# MEC1322 register map
Vendor: Microchip Technology Inc.; Series: ARMCM4F; File version: 1.0
CPU: CM4 r1p0, little endian, MPU, FPU, 3 interrupt priority bits
Registers are 32-bit, read-write, reset 0x0 unless marked. A register's access mark holds for its fields unless they carry their own. Offsets are from the block's base; [hi:lo] are bit positions; {n}, {i} and the like mark numbered series.

## BC_LINK — This block provides BC-Link? connectivity to a slave device. The BC-Link protocol includes a start bit to signal the beginning of a message and a turnaround (TAR) period for bus transfer between the Master and Companion devices.
Base 0x4000BC00
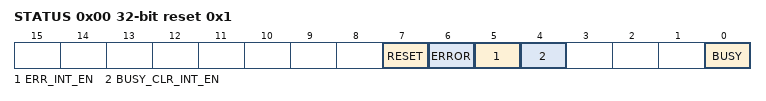
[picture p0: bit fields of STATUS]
0x00 STATUS reset 0x1 — BC-Link Status
  [7] RESET — When this bit is '1'the BC_Link Master Interface will be placed in reset and be held in reset until this bit is cleared to '0'. Setting RESET to '1' causes the BUSY bit to be set to '1'. The BUSY remains set to '1' until the reset operation of the BC Interface is completed, which takes approximately 48 BC clocks.
  [6] ERROR — This bit indicates that a BC Bus Error has occurred. (R/WC)
  [5] ERR_INT_EN — This bit is an enable for generating an interrupt when the BC_ERR bit is set by hardware. When this bit is '1', the interrupt signal is enabled. When this bit is '0', the interrupt is disabled.
  [4] BUSY_CLR_INT_EN — This bit is an enable for generating an interrupt when the BUSY bit in this register is cleared by hardware. When this bit is set to '1', the interrupt signal is enabled. When the this bit is cleared to '0', the interrupt is disabled. When enabled, the interrupt occurs after a BC Bus read or write.
  [0] BUSY read — This bit is asserted to '1' when the BC interface is transferring data and on reset.
0x04 ADDRESS — BC-Link Address Register [7:0] Address in the Companion for the BC-Link transaction.
0x08 DATA — BC-Link Data Register [7:0] this register hold data used in a BC-Link transaction.
0x0C CLOCK_SELECT — BC-Link Clock Select Register [7:0] DIVIDER The BC Clock is set to the Master Clock divided by this field, or 48MHz/ (Divider +1). The clock divider bits can only can be changed when the BC Bus is in soft RESET (when either the Reset bit is set by software or when the BUSY bit is set by the interface).

## TFDP — The TFDP serially transmits Embedded Controller (EC)-originated diagnostic vectors to an external debug trace system.
Base 0x40008C00
0x00 DATA 16-bit — Debug data to be shifted out on the TFDP Debug port. While data is being shifted out, the Host Interface will 'hold-off' additional writes to the data register until the transfer is complete.
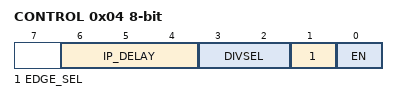
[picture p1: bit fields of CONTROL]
0x04 CONTROL 8-bit — Debug Control Register
  [6:4] IP_DELAY — Inter-packet Delay. The delay is in terms of TFDP Debug output clocks.
  [3:2] DIVSEL — Clock Divider Select.
  [1] EDGE_SEL — 1= Data is shifted out on the falling edge of the debug clock, 0= Data is shifted out on the rising edge of the debug clock (Default)
  [0] EN — Enable. 1=Clock enabled, 0=Clock is disabled (Default)

## ADC — This block is designed to convert external analog voltage readings into digital values.
Base 0x40007C00
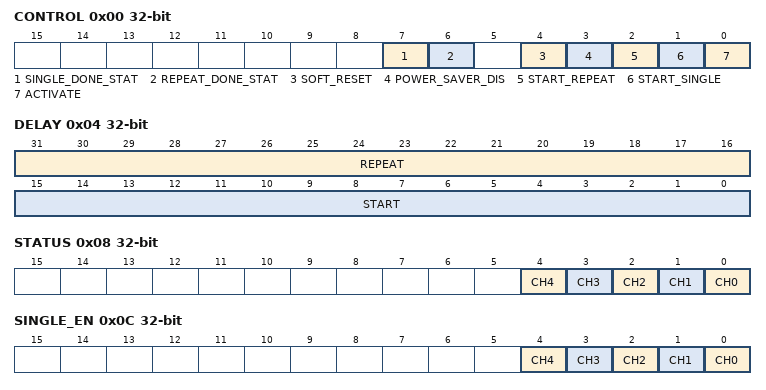
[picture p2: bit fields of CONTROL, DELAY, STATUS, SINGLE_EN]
0x00 CONTROL — The ADC Control Register is used to control the behavior of the Analog to Digital Converter.
  [7] SINGLE_DONE_STAT — 0: ADC single-sample conversion is not complete. 1: ADC single-sample conversion is completed.
  [6] REPEAT_DONE_STAT — 0: ADC repeat-sample conversion is not complete. 1: ADC repeat-sample conversion is completed.
  [4] SOFT_RESET — (SOFT_RESET) 1: writing one causes a reset of the ADC block hardware (not the registers) 0: writing zero takes the ADC block out of reset
  [3] POWER_SAVER_DIS — 0: Power saving feature is enabled. 1: Power saving feature is disabled.
  [2] START_REPEAT — 0: The ADC Repeat Mode is disabled. 1: The ADC Repeat Mode is enabled.
  [1] START_SINGLE — (START_SINGLE) 0: The ADC Single Mode is disabled. 1: The ADC Single Mode is enabled. Note: This bit is self-clearing
  [0] ACTIVATE — 0: The ADC is disabled and placed in its lowest power state. 1: ADC block is enabled for operation.
0x04 DELAY (reset mask 0xFFFF) — The ADC Delay register determines the delay from setting Start_Repeat in the ADC Control Register and the start of a conversion cycle. This register also controls the interval between conversion cycles in repeat mode.
  [31:16] REPEAT — This field determines the interval between conversion cycles when Start_Repeat is 1.
  [15:0] START — This field determines the starting delay before a conversion cycle is begun when Start_Repeat is written with a 1.
0x08 STATUS — The ADC Status Register indicates whether the ADC has completed a conversion cycle. All bits are cleared by being written with a '1'. 0: conversion of the corresponding ADC channel is not complete. 1: conversion of the corresponding ADC channel is complete
  [n] CH{n} (n=0..4) — ADC_Ch{n}_Status
0x0C SINGLE_EN — The ADC Single Register is used to control which ADC channel is captured during a Single-Sample conversion cycle initiated by the Start_Single bit in the ADC Control Register. APPLICATION NOTE: Do not change the bits in this register in the middle of a conversion cycle to insure proper operation. 0: single cycle conversions for this channel are disabled. 1: single cycle conversions for this channel are enabled
  [n] CH{n} (n=0..4) — ADC Ch{n} single cycle conversions for this channel are 1:enabled/0:disabled
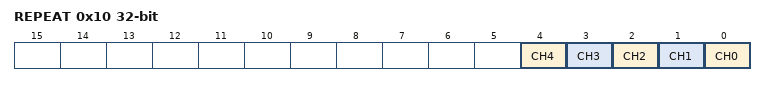
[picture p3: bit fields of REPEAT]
0x10 REPEAT — The ADC Repeat Register is used to control which ADC channels are captured during a repeat conversion cycle initiated by the Start_Repeat bit in the ADC Control Register.
  [n] CH{n} (n=0..4) — ADC Ch{n} repeat conversions for this channel are 1:enabled/0:disabled
{0x14+4i} READ[{i}] (i=0..4) — All 5 ADC channels return their results into a 32-bit reading register. In each case the low 10 bits of the reading register return the result of the Analog to Digital conversion and the upper 22 bits return 0.

## EC_REG_BANK — This block is designed to be accessed internally by the EC via the register interface.
Base 0x4000FC00
0x14 AHB_ERROR_CONTROL 8-bit — AHB Error Control [0:0] AHB_ERROR_DISABLE, 0: EC memory exceptions are enabled. 1: EC memory exceptions are disabled.
0x18 INTERRUPT_CONTROL reset 0x1 — Interrupt Control [0:0] NVIC_EN (NVIC_EN) This bit enables Alternate NVIC IRQ's Vectors. The Alternate NVIC Vectors provides each interrupt event with a dedicated (direct) NVIC vector. 0 = Alternate NVIC vectors disabled, 1= Alternate NVIC vectors enabled
0x1C ETM_TRACE_ENABLE — ETM TRACE Enable [0:0] TRACE_EN (TRACE_EN) This bit enables the ARM TRACE debug port (ETM/ITM). The Trace Debug Interface pins are forced to the TRACE functions. 0 = ARM TRACE port disabled, 1= ARM TRACE port enabled
0x20 JTAG_Enable — JTAG Enable [0:0] JTAG_EN (JTAG_EN) This bit enables the JTAG debug port. 0 = JTAG port disabled. JTAG cannot be enabled (i.e., the TRST# pin is ignored and the JTAG signals remain in their non-JTAG state). 1= JTAG port enabled. A high on TRST# enables JTAG
0x28 WDT_EVENT_COUNT — WDT Event Count [3:0] WDT_COUNT (WDT_COUNT) These EC R/W bits are cleared to 0 on VCC1 POR, but not on a WDT. Note: This field is written by Boot ROM firmware to indicate the number of times a WDT fired before loading a good EC code image.
0x38 ADC_VREF_PD — ADC VREF PD [0:0] ADC_VREF_PD_REF (ADC_VREF_PD_REF) ADC VREF Power down. 0=on 1=off

## JTAG — The Controller, which is an IEEE compliant JTAG Port, has implemented all the mandatory JTAG instructions. This interface may be used to access the embedded controller's test access port (TAP).
Base 0x40080000
0x00 MESSAGE_OBF — JTAG Message OBF
0x04 MESSAGE_IBF — JTAG Message IBF
0x08 OBF_STATUS 8-bit — JTAG OBF Status
0x09 IBF_STATUS 8-bit — JTAG IBF Status
0x0C DBG_CTRL — JTAG DBG Ctrl
